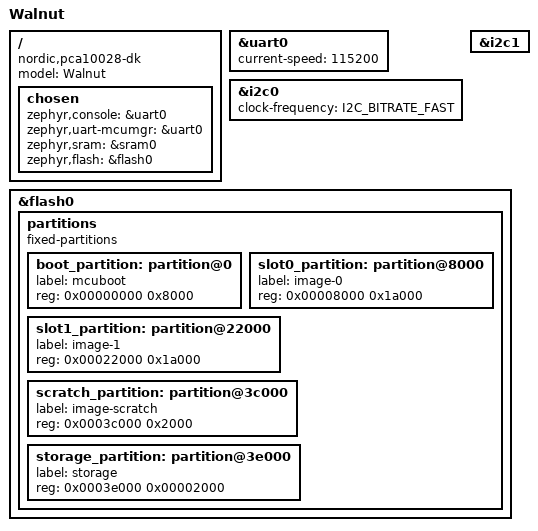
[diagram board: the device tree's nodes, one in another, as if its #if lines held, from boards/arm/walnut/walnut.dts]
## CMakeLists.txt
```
# Re-direct the directory where the 'boards' directory is found from
# $ZEPHYR_BASE to this directory.
set(BOARD_ROOT ${CMAKE_CURRENT_LIST_DIR})

set(BOARD walnut)

if(NOT BOARD_VARIANT)
    set(BOARD_VARIANT climate)
endif()

add_definitions(-DBOARD_VARIANT=${BOARD_VARIANT})

macro(set_conf_file)
    if(EXISTS ${APPLICATION_SOURCE_DIR}/boards/arm/walnut/${BOARD}_${BOARD_VARIANT}.conf)
        set(CONF_FILE "prj.conf ${APPLICATION_SOURCE_DIR}/boards/arm/walnut/${BOARD}_${BOARD_VARIANT}.conf")
    else()
        set(CONF_FILE "prj.conf")
    endif()
endmacro()

include($ENV{ZEPHYR_BASE}/cmake/app/boilerplate.cmake NO_POLICY_SCOPE)
project(NONE)

add_subdirectory(drivers)

FILE(GLOB app_sources src/*.c)
target_sources(app PRIVATE ${app_sources})
target_include_directories(app PRIVATE $ENV{ZEPHYR_BASE}/subsys/fs/nvs)
```

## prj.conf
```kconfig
#CONFIG_BT=y
CONFIG_BT_PERIPHERAL=y
CONFIG_BT_SMP=y
CONFIG_TINYCRYPT=y
CONFIG_BT_DEVICE_NAME="Walnut"
CONFIG_BT_DEVICE_APPEARANCE=0

#CONFIG_NEWLIB_LIBC=y
#CONFIG_NEWLIB_LIBC_FLOAT_PRINTF=y

#CONFIG_ASSERT=y
#CONFIG_ASSERT_LEVEL=2
#CONFIG_NUM_COOP_PRIORITIES=29
#CONFIG_NUM_PREEMPT_PRIORITIES=40

#CONFIG_SYS_POWER_MANAGEMENT=y
#CONFIG_SYS_POWER_LOW_POWER_STATE=y
#CONFIG_SYS_POWER_DEEP_SLEEP=y
#CONFIG_DEVICE_POWER_MANAGEMENT=y
#CONFIG_TICKLESS_IDLE=y
#CONFIG_TICKLESS_KERNEL=y
#CONFIG_GPIO=y

#CONFIG_MULTITHREADING=y

CONFIG_FLASH=y

CONFIG_NVS=y
CONFIG_NVS_LOG=y
CONFIG_NVS_LOG_LEVEL=4
CONFIG_REBOOT=y
```

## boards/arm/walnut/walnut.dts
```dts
/*
 * Copyright (c) 2017 Linaro Limited
 *
 * SPDX-License-Identifier: Apache-2.0
 */

/dts-v1/;
#include <nordic/nrf51822.dtsi>

/ {
	model = "Walnut";
	compatible = "nordic,pca10028-dk", "nordic,nrf51822-qfac",
		     "nordic,nrf51822";

	chosen {
		zephyr,console = &uart0;
#ifdef CONFIG_MCUMGR_SMP_UART
		zephyr,uart-mcumgr = &uart0;
#endif
		zephyr,sram = &sram0;
		zephyr,flash = &flash0;
	};
};

&uart0 {
	current-speed = <115200>;
	status = "ok";
};

&i2c0 {
	status = "ok";
	clock-frequency = <I2C_BITRATE_FAST>;
};

&i2c1 {
	status = "ok";
};

&flash0 {
	/*
	 * For more information, see:
	 * http://docs.zephyrproject.org/devices/dts/flash_partitions.html
	 */
	partitions {
		compatible = "fixed-partitions";
		#address-cells = <1>;
		#size-cells = <1>;

		boot_partition: partition@0 {
			label = "mcuboot";
			reg = <0x00000000 0x8000>;
		};
		slot0_partition: partition@8000 {
			label = "image-0";
			reg = <0x00008000 0x1a000>;
		};
		slot1_partition: partition@22000 {
			label = "image-1";
			reg = <0x00022000 0x1a000>;
		};
		scratch_partition: partition@3c000 {
			label = "image-scratch";
			reg = <0x0003c000 0x2000>;
		};

#if defined(CONFIG_FS_FLASH_STORAGE_PARTITION)
		storage_partition: partition@3e000 {
			label = "storage";
			reg = <0x0003e000 0x00002000>;
		};
#endif
	};
};
```

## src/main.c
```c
/* main.c - Application main entry point */

/*
 * Copyright (c) 2016 Intel Corporation
 *
 * SPDX-License-Identifier: Apache-2.0
 */

#include <stdint.h>
#include <zephyr.h>
#include <sensor.h>

#include "fg.h"
#include "nv.h"
#include "ble.h"
#include "ess.h"
#include "t_rh_sens.h"
#include "als.h"
#include "bp_sens.h"

#define CONFIG_SYS_LOG_MAIN_LEVEL 4

#define SYS_LOG_DOMAIN "app"
#define SYS_LOG_LEVEL CONFIG_SYS_LOG_MAIN_LEVEL
#include <logging/sys_log.h>


static void fg_update_cb(uint8_t battery_capacity)
{
    SYS_LOG_INF("Battery_capacity=%d", battery_capacity);
    ble_update_battery(battery_capacity);
}

static void t_rh_meas_cb(t_rh_meas_t *measurement)
{
    if (measurement->temperature_updated) {
        struct sensor_value *temperature = (struct sensor_value *)measurement->temperature;
        SYS_LOG_INF("T:%d.%06d", temperature->val1, temperature->val2);
        ble_update_temp(sensor_value_to_double(temperature));
    }

    if (measurement->humidity_updated) {
        struct sensor_value *humidity = (struct sensor_value *)measurement->humidity;
        SYS_LOG_INF("RH:%d.%06d", humidity->val1, humidity->val2);
        ble_update_humidity(sensor_value_to_double(humidity));
    }
}

static void al_meas_cb(struct sensor_value *ambient_light)
{
    SYS_LOG_INF("AL:%d.%06d", ambient_light->val1, ambient_light->val2);
    ble_update_ambient_light(sensor_value_to_double(ambient_light));
}

static void bp_meas_cb(struct sensor_value *baro_pressure)
{
    SYS_LOG_INF("AL:%d.%06d", baro_pressure->val1, baro_pressure->val2);
    ble_update_baro_pressure(sensor_value_to_double(baro_pressure));
}


void main(void)
{
    SYS_LOG_INF("Starting app");

    fg_init(fg_update_cb);
    nv_init();
    t_rh_sens_init(t_rh_meas_cb);
    als_init(al_meas_cb);
    bp_sens_init(bp_meas_cb);
    ble_init();

    while (1) {
        k_sleep(10 * MSEC_PER_SEC);
    }
}
```

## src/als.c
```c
/**
 *
 *
 *
 */

#include <stdlib.h>
#include <kernel.h>
#include <sensor.h>

#include "als.h"
#include "nv.h"
#include "ess.h"

#define CONFIG_SYS_LOG_ALS_LEVEL 1
#define SYS_LOG_DOMAIN "als"
#define SYS_LOG_LEVEL CONFIG_SYS_LOG_ALS_LEVEL
#include <logging/sys_log.h>


static struct device *tsl4531_dev;
static struct sensor_value als_val;
static struct k_timer meas_timer;
static struct k_work meas_work;
static als_meas_cb_t meas_cb;

static nv_sensor_data_t _default_sensor_data = {
    .sampling_func    = ESS_SAMPL_FUNC_INSTANTANEOUS,
    .meas_period      = ESS_MEAS_PERIOD_NOT_IN_USE,
    .update_interval  = 60,
    .application      = ESS_APPL_Air,
    .meas_uncertainty = 0,
};

static void meas_work_handler(struct k_work *work);
static void meas_timer_handler(struct k_timer *timer);


static void meas_work_handler(struct k_work *work)
{
    SYS_LOG_DBG("Periodic als measurement");
    als_meas();

    if (meas_cb != NULL) {
        meas_cb(&als_val);
    }
}

static void meas_timer_handler(struct k_timer *timer)
{
    k_work_submit(&meas_work);
}

int als_meas(void)
{
#ifdef CONFIG_TSL4531
    if (sensor_sample_fetch(tsl4531_dev)) {
        SYS_LOG_ERR("Error fetching tsl4531 sample");
        return -1;
    }

    if (sensor_channel_get(tsl4531_dev, SENSOR_CHAN_LIGHT, &als_val)) {
        SYS_LOG_ERR("Error reading tsl4531 data");
        return -1;
    } else {
        // SYS_LOG_DBG("AL:%d.%d", (int)sensor_value_to_double(&als_val),
        //             (int)(sensor_value_to_double(&als_val) * 100) % 100);
        // SYS_LOG_DBG("RH1:%d", rh_sensor_value.val1);
        // SYS_LOG_DBG("RH2:%d", rh_sensor_value.val2);
        SYS_LOG_INF("ALS:%d.%06d", als_val.val1, als_val.val2);
    }
#endif
    return 0;
}

void als_init(als_meas_cb_t callback)
{
#ifdef CONFIG_TSL4531
    int err;
    nv_sensor_data_t sensor_data;

    meas_cb = callback;

    tsl4531_dev = device_get_binding(CONFIG_TSL4531_NAME);
    if (tsl4531_dev == NULL) {
        SYS_LOG_ERR("Failed to get pointer to %s device!", CONFIG_TSL4531_NAME);
    }

    err = nv_get_sensor_data(NV_SENSOR_AMBIENT_LIGHT, &sensor_data);
    if (err == -ENOENT) {
        nv_set_sensor_data(NV_SENSOR_AMBIENT_LIGHT, &_default_sensor_data);
        nv_get_sensor_data(NV_SENSOR_AMBIENT_LIGHT, &sensor_data);
    }

    k_work_init(&meas_work, meas_work_handler);
    k_timer_init(&meas_timer, meas_timer_handler, NULL);
    k_timer_start(&meas_timer, K_SECONDS(5), K_SECONDS(sensor_data.update_interval));
#endif
}
```

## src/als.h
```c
/**
 *
 *
 */

#ifndef ALS_H
#define ALS_H

typedef void (*als_meas_cb_t)(struct sensor_value *ambient_light);

void als_init(als_meas_cb_t callback);
int als_meas(void);

#endif /* ALS_H */
```

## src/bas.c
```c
/** @file
 *  @brief BAS Service sample
 */

/*
 * Copyright (c) 2016 Intel Corporation
 *
 * SPDX-License-Identifier: Apache-2.0
 */

#include <zephyr/types.h>
#include <stddef.h>
#include <string.h>
#include <errno.h>
#include <misc/printk.h>
#include <misc/byteorder.h>
#include <zephyr.h>

#include <bluetooth/bluetooth.h>
#include <bluetooth/hci.h>
#include <bluetooth/conn.h>
#include <bluetooth/uuid.h>
#include <bluetooth/gatt.h>

static struct bt_gatt_ccc_cfg  blvl_ccc_cfg[BT_GATT_CCC_MAX] = {};
static u8_t is_notify_enabled;
static u8_t battery = 100;

static void blvl_ccc_cfg_changed(const struct bt_gatt_attr *attr,
                 u16_t value)
{
    is_notify_enabled = (value == BT_GATT_CCC_NOTIFY) ? 1 : 0;
}

static ssize_t read_blvl(struct bt_conn *conn, const struct bt_gatt_attr *attr,
             void *buf, u16_t len, u16_t offset)
{
    const char *value = attr->user_data;

    return bt_gatt_attr_read(conn, attr, buf, len, offset, value,
                 sizeof(*value));
}

/* Battery Service Declaration */
static struct bt_gatt_attr attrs[] = {
    BT_GATT_PRIMARY_SERVICE(BT_UUID_BAS),
    BT_GATT_CHARACTERISTIC(BT_UUID_BAS_BATTERY_LEVEL,
                   BT_GATT_CHRC_READ | BT_GATT_CHRC_NOTIFY,
                   BT_GATT_PERM_READ, read_blvl, NULL, &battery),
    BT_GATT_CCC(blvl_ccc_cfg, blvl_ccc_cfg_changed),
};

static struct bt_gatt_service bas_svc = BT_GATT_SERVICE(attrs);

void bas_init(void)
{
    bt_gatt_service_register(&bas_svc);
}

void bas_update(uint8_t capacity)
{
    battery = capacity;

    if (!is_notify_enabled) {
        return;
    }

    bt_gatt_notify(NULL, &attrs[2], &battery, sizeof(battery));
}
```

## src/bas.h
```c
/** @file
 *  @brief BAS Service sample
 */

/*
 * Copyright (c) 2016 Intel Corporation
 *
 * SPDX-License-Identifier: Apache-2.0
 */

#ifndef BAS_H
#define BAS_H

void bas_init(void);
void bas_update(uint8_t capacity);

#endif /* BAS_H */
```

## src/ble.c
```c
/**
 *
 *
 *
 */

#include <stdbool.h>
#include <zephyr/types.h>
#include <stddef.h>
#include <string.h>
#include <errno.h>
#include <misc/printk.h>
#include <misc/byteorder.h>
#include <zephyr.h>

#include <bluetooth/bluetooth.h>
#include <bluetooth/hci.h>
#include <bluetooth/conn.h>
#include <bluetooth/uuid.h>
#include <bluetooth/gatt.h>

#include "bas.h"
#include "dis.h"
#include "ess.h"

#define SYS_LOG_DOMAIN "BLE"
// #define SYS_LOG_LEVEL CONFIG_SYS_LOG_SENSOR_LEVEL
#include <logging/sys_log.h>

#define DEVICE_NAME				CONFIG_BT_DEVICE_NAME
#define DEVICE_NAME_LEN				(sizeof(DEVICE_NAME) - 1)

#ifndef BUILD_VERSION
#define BUILD_VERSION UNKNOWN
#endif

#define DEVICE_SOFTWARE_VERSION     STRINGIFY(BUILD_VERSION)
#define DEVICE_HARDWARE_VERSION     STRINGIFY(BOARD_VARIANT)

#define ESS_ADV_SLOW BT_LE_ADV_PARAM(BT_LE_ADV_OPT_CONNECTABLE, \
                       BT_GAP_ADV_SLOW_INT_MIN, \
                       BT_GAP_ADV_SLOW_INT_MAX)

#define ESS_ADV_FAST_1 BT_LE_ADV_PARAM(BT_LE_ADV_OPT_CONNECTABLE, \
                       BT_GAP_ADV_FAST_INT_MIN_1, \
                       BT_GAP_ADV_FAST_INT_MAX_1)

#define ESS_ADV_FAST_2 BT_LE_ADV_PARAM(BT_LE_ADV_OPT_CONNECTABLE, \
                       BT_GAP_ADV_FAST_INT_MIN_2, \
                       BT_GAP_ADV_FAST_INT_MAX_2)

// Default Device Information Service data
static dis_data_t dis_data = {
    .sw_rev = DEVICE_SOFTWARE_VERSION,
    .hw_rev = DEVICE_HARDWARE_VERSION,
};


static uint8_t batt[3] = { 0x0f, 0x18, 0x00 };

static struct bt_data ad[] = {
    BT_DATA_BYTES(BT_DATA_FLAGS, (BT_LE_AD_GENERAL | BT_LE_AD_NO_BREDR)),
    BT_DATA_BYTES(BT_DATA_UUID16_SOME, 0x1a, 0x18),
    BT_DATA(BT_DATA_NAME_COMPLETE, DEVICE_NAME, DEVICE_NAME_LEN),
    BT_DATA(BT_DATA_SVC_DATA16, batt, 3),
};

// static struct bt_data sd[] = {
//     BT_DATA(BT_DATA_NAME_COMPLETE, DEVICE_NAME, DEVICE_NAME_LEN),
// };

static void connected(struct bt_conn *conn, u8_t err)
{
    if (err) {
        SYS_LOG_ERR("Connection failed (err %u)", err);
    } else {
        SYS_LOG_DBG("Connected");


    // struct bt_le_conn_param param = {
    //     .interval_min = 24,
    //     // .interval_max = 40,
    //     .interval_max = 100,
    //     .latency = 0,
    //     .timeout = 400,
    // };
    // bt_conn_le_param_update(conn, &param);

    struct bt_conn_info info;
    bt_conn_get_info(conn, &info);

    struct bt_conn_le_info *le = &info.le;

    SYS_LOG_INF("Interval:%d", le->interval);
    SYS_LOG_INF("Latency:%d", le->latency);
    SYS_LOG_INF("Timeout:%d", le->timeout);

        // struct bt_le_conn_param param = {
        //     .interval_min = 24,
        //     .interval_max = 40,
        //     .latency = 0,
        //     .timeout = 400,
        // };
        // bt_conn_le_param_update(conn, &param);
    }
}

static void disconnected(struct bt_conn *conn, u8_t reason)
{
    SYS_LOG_DBG("Disconnected (reason %u)", reason);
}

static void le_param_updated(struct bt_conn *conn, u16_t interval,
                u16_t latency, u16_t timeout)
{
    SYS_LOG_INF("U:Interval:%d", interval);
    SYS_LOG_INF("U:Latency:%d", latency);
    SYS_LOG_INF("U:Timeout:%d", timeout);
}

static struct bt_conn_cb conn_callbacks = {
    .connected = connected,
    .disconnected = disconnected,
    .le_param_updated = le_param_updated,
};

static void bt_ready(int err)
{
    if (err) {
        SYS_LOG_ERR("Bluetooth init failed (err %d)", err);
        return;
    }

    SYS_LOG_INF("Bluetooth initialized");

    dis_init(&dis_data);
    ess_init();
    bas_init();

    err = bt_le_adv_start(ESS_ADV_SLOW, ad, ARRAY_SIZE(ad),
                //   sd, ARRAY_SIZE(sd));
                  NULL, 0);
    if (err) {
        SYS_LOG_ERR("Advertising failed to start (err %d)", err);
        return;
    }

    SYS_LOG_INF("Advertising successfully started");
}

static void auth_passkey_display(struct bt_conn *conn, unsigned int passkey)
{
    char addr[BT_ADDR_LE_STR_LEN];

    bt_addr_le_to_str(bt_conn_get_dst(conn), addr, sizeof(addr));

    printk("Passkey for %s: %06u", addr, passkey);
}

static void auth_cancel(struct bt_conn *conn)
{
    char addr[BT_ADDR_LE_STR_LEN];

    bt_addr_le_to_str(bt_conn_get_dst(conn), addr, sizeof(addr));

    printk("Pairing cancelled: %s", addr);
}

static struct bt_conn_auth_cb auth_cb_display = {
    .passkey_display = auth_passkey_display,
    .passkey_entry = NULL,
    .cancel = auth_cancel,
};

static void adv_update(uint8_t batt_capacity)
{
    int err;

    err = bt_le_adv_stop();
    if (err) {
        SYS_LOG_ERR("Failed to stop advertising");
    }

    batt[2] = batt_capacity;

    err = bt_le_adv_start(ESS_ADV_SLOW, ad, ARRAY_SIZE(ad), NULL, 0);
    if (err) {
        SYS_LOG_ERR("start error");
    }
}

void ble_update_temp(double temperature)
{
    ess_temperature_update((int16_t)(100 * temperature));
}

void ble_update_humidity(double humidity)
{
    ess_humidity_update((int16_t)(100 * humidity));
}

void ble_update_ambient_light(double ambient_light)
{
    ess_als_update((int16_t)(100 * ambient_light));
}

void ble_update_baro_pressure(double pressure)
{
    ess_baro_press_update((uint32_t)(10000 * pressure));
}

void ble_update_battery(uint8_t battery_capacity)
{
    adv_update(battery_capacity);
    bas_update(battery_capacity);
}

void ble_init(void)
{
    int err;

    SYS_LOG_INF("Initializing BLE");

    err = bt_enable(bt_ready);
    if (err) {
        SYS_LOG_ERR("Bluetooth init failed (err %d)", err);
        return;
    }

    bt_conn_cb_register(&conn_callbacks);
    bt_conn_auth_cb_register(&auth_cb_display);
}
```

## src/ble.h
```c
/**
 *
 *
 */
#ifndef BLE_H
#define BLE_H

void ble_init(void);

void ble_update_temp(double temperature);
void ble_update_humidity(double humidity);
void ble_update_ambient_light(double ambient_light);
void ble_update_baro_pressure(double pressure);
void ble_update_battery(uint8_t battery_capacity);

#endif /* BLE_H */
```

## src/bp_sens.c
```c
/**
 *
 *
 *
 */

#include <stdlib.h>
#include <kernel.h>
#include <sensor.h>

#include "bp_sens.h"
#include "nv.h"
#include "ess.h"

#define CONFIG_SYS_LOG_BP_SENS_LEVEL 1
#define SYS_LOG_DOMAIN "bp_sens"
#define SYS_LOG_LEVEL CONFIG_SYS_LOG_BP_SENS_LEVEL
#include <logging/sys_log.h>


static struct device *bmp280_dev;
static struct sensor_value bp_val;
static struct k_timer meas_timer;
static struct k_work meas_work;
static bp_meas_cb_t meas_cb;

static nv_sensor_data_t _default_sensor_data = {
    .sampling_func    = ESS_SAMPL_FUNC_INSTANTANEOUS,
    .meas_period      = ESS_MEAS_PERIOD_NOT_IN_USE,
    .update_interval  = 60,
    .application      = ESS_APPL_Air,
    .meas_uncertainty = 0,
};

static void meas_work_handler(struct k_work *work);
static void meas_timer_handler(struct k_timer *timer);


static void meas_work_handler(struct k_work *work)
{
    SYS_LOG_DBG("Periodic barometric pressure measurement");
    bp_sens_meas();

    if (meas_cb != NULL) {
        meas_cb(&bp_val);
    }

}

static void meas_timer_handler(struct k_timer *timer)
{
    k_work_submit(&meas_work);
}

void bp_sens_meas(void)
{
    int err;

    err = sensor_sample_fetch(bmp280_dev);
    if (err != 0) {
        SYS_LOG_ERR("Error fetching barometric pressure sample");
        return;
    }

    err = sensor_channel_get(bmp280_dev, SENSOR_CHAN_PRESS, &bp_val);
    if (err != 0) {
        SYS_LOG_ERR("Error reading bmp280 data");
    } else {
        SYS_LOG_INF("BP:%d.%06d", bp_val.val1, bp_val.val2);
    }
}

void bp_sens_init(bp_meas_cb_t callback)
{
#ifdef CONFIG_BMP280
    int err;
    nv_sensor_data_t sensor_data;

    meas_cb = callback;

    bmp280_dev = device_get_binding(CONFIG_BMP280_DEV_NAME);
    if (bmp280_dev == NULL) {
        SYS_LOG_ERR("Failed to get pointer to %s device!", CONFIG_BMP280_DEV_NAME);
    }

    err = nv_get_sensor_data(NV_SENSOR_BARO_PRESSURE, &sensor_data);
    if (err == -ENOENT) {
        nv_set_sensor_data(NV_SENSOR_BARO_PRESSURE, &_default_sensor_data);
        nv_get_sensor_data(NV_SENSOR_BARO_PRESSURE, &sensor_data);
    }

    k_work_init(&meas_work, meas_work_handler);
    k_timer_init(&meas_timer, meas_timer_handler, NULL);
    k_timer_start(&meas_timer, K_SECONDS(5), K_SECONDS(sensor_data.update_interval));
#endif
}
```

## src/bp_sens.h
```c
/**
 *
 *
 */

#ifndef BP_SENS_H
#define BP_SENS_H

typedef void (*bp_meas_cb_t)(struct sensor_value *baro_pressure);

void bp_sens_init(bp_meas_cb_t callback);
void bp_sens_meas(void);

#endif /* BP_SENS_H */
```

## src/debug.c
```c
    // u32_t *hej = (u32_t *)0x40003500;
    // SYS_LOG_INF("P:%p V:0x%08x V2:0x%08x", hej, *hej, *(u32_t *)0x40003500);
    // hej = (u32_t *)0x40003508;
    // SYS_LOG_INF("P:%p V:0x%08x V2:0x%08x", hej, *hej, *(u32_t *)0x40003508);
    // hej = (u32_t *)0x4000350C;
    // SYS_LOG_INF("P:%p V:0x%08x V2:0x%08x", hej, *hej, *(u32_t *)0x4000350C);

    // u32_t *gpio_out = (u32_t *)0x50000504;
    // u32_t *gpio_in = (u32_t *)0x50000510;
    // u32_t *gpio_dir = (u32_t *)0x50000514;
    // u32_t *gpio_pin_cnf_13 = (u32_t *)0x50000734;

    // SYS_LOG_INF("gpio_out P:%p V:0x%08x", gpio_out, *gpio_out);
    // SYS_LOG_INF("gpio_in P:%p V:0x%08x", gpio_in, *gpio_in);
    // SYS_LOG_INF("gpio_dir P:%p V:0x%08x", gpio_dir, *gpio_dir);
    // SYS_LOG_INF("gpio_pin_cnf_13 P:%p V:0x%08x", gpio_pin_cnf_13, *gpio_pin_cnf_13);
```

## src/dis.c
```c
/** @file
 *  @brief DIS Service sample
 */

/*
 * Copyright (c) 2016 Intel Corporation
 *
 * SPDX-License-Identifier: Apache-2.0
 */

#include <zephyr/types.h>
#include <stddef.h>
#include <string.h>
#include <errno.h>
#include <misc/printk.h>
#include <misc/byteorder.h>
#include <zephyr.h>

#include <bluetooth/bluetooth.h>
#include <bluetooth/hci.h>
#include <bluetooth/conn.h>
#include <bluetooth/uuid.h>
#include <bluetooth/gatt.h>

#include "dis.h"

// Device Information Service data
static dis_data_t *dis;

// Function prototype for reading software version
static ssize_t read_sw_vers(struct bt_conn *conn,
              const struct bt_gatt_attr *attr, void *buf,
              u16_t len, u16_t offset);

// Function prototype for reading hardware version
static ssize_t read_hw_vers(struct bt_conn *conn,
              const struct bt_gatt_attr *attr, void *buf,
              u16_t len, u16_t offset);

/* Device Information Service Declaration */
static struct bt_gatt_attr attrs[] = {
    BT_GATT_PRIMARY_SERVICE(BT_UUID_DIS),
    BT_GATT_CHARACTERISTIC(BT_UUID_DIS_SOFTWARE_REVISION,
                   BT_GATT_CHRC_READ, BT_GATT_PERM_READ,
                   read_sw_vers, NULL, NULL),
    BT_GATT_CHARACTERISTIC(BT_UUID_DIS_HARDWARE_REVISION,
                   BT_GATT_CHRC_READ, BT_GATT_PERM_READ,
                   read_hw_vers, NULL, NULL),
};
static struct bt_gatt_service dis_svc = BT_GATT_SERVICE(attrs);


/**
* @private
* @brief Callback to read the software version characteristic
*/
static ssize_t read_sw_vers(struct bt_conn *conn,
              const struct bt_gatt_attr *attr, void *buf,
              u16_t len, u16_t offset)
{
    return bt_gatt_attr_read(conn, attr, buf, len, offset, dis->sw_rev,
                 strlen(dis->sw_rev));
}

/**
* @private
* @brief Callback to read the hardware version characteristic
*/
static ssize_t read_hw_vers(struct bt_conn *conn,
              const struct bt_gatt_attr *attr, void *buf,
              u16_t len, u16_t offset)
{
    return bt_gatt_attr_read(conn, attr, buf, len, offset, dis->hw_rev,
                 strlen(dis->hw_rev));
}


/****************************************************************************
* Public Function Definitions
***************************************************************************/

void dis_init(dis_data_t *dis_data)
{
    dis = dis_data;

    bt_gatt_service_register(&dis_svc);
}
```

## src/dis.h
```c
/** @file
 *  @brief DIS Service sample
 */

/*
 * Copyright (c) 2016 Intel Corporation
 *
 * SPDX-License-Identifier: Apache-2.0
 */

#ifndef _DIS_H_
#define _DIS_H_

typedef struct {
    char *sw_rev;
    char *hw_rev;
} dis_data_t;

void dis_init(dis_data_t *dis_data);

#endif  /* _DIS_H_ */
```

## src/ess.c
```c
/** @file
 *  @brief Environmental Sensor Service
 */

/****************************************************************************
* Include Directives
***************************************************************************/

#include <zephyr/types.h>
#include <stddef.h>
#include <string.h>
#include <errno.h>
#include <misc/printk.h>
#include <misc/byteorder.h>
#include <zephyr.h>

#include <bluetooth/bluetooth.h>
#include <bluetooth/hci.h>
#include <bluetooth/conn.h>
#include <bluetooth/uuid.h>
#include <bluetooth/gatt.h>

#include "ess.h"
#include "nv.h"

#define SYS_LOG_DOMAIN "ESS"
#define SYS_LOG_LEVEL 1
#include <logging/sys_log.h>


/****************************************************************************
* Preprocessor Directives
***************************************************************************/

#define TEMPERATURE_SENSOR_NAME     "Temperature Sensor"
#define HUMIDITY_SENSOR_NAME        "Humidity Sensor"
#define AMBIENT_LIGHT_SENSOR_NAME   "Ambient Light Sensor"
#define BARO_PRESSURE_SENSOR_NAME   "Barometric Pressure Sensor"

/* ESS Trigger Setting conditions */
#define ESS_TRIGGER_INACTIVE                0x00
#define ESS_FIXED_TIME_INTERVAL             0x01
#define ESS_NO_LESS_THAN_SPECIFIED_TIME     0x02
#define ESS_VALUE_CHANGED                   0x03
#define ESS_LESS_THAN_REF_VALUE             0x04
#define ESS_LESS_OR_EQUAL_TO_REF_VALUE      0x05
#define ESS_GREATER_THAN_REF_VALUE          0x06
#define ESS_GREATER_OR_EQUAL_TO_REF_VALUE   0x07
#define ESS_EQUAL_TO_REF_VALUE              0x08
#define ESS_NOT_EQUAL_TO_REF_VALUE          0x09


/****************************************************************************
* Private Type Declarations
***************************************************************************/

struct ess_meas_desc {
    u16_t flags; /* Reserved for Future Use */
    u8_t sampling_func;
    u32_t meas_period;
    u32_t update_interval;
    u8_t application;
    u8_t meas_uncertainty;
};

struct ess_sensor {
    s16_t value;

    /* Valid Range */
    s16_t lower_limit;
    s16_t upper_limit;

    /* ES trigger setting - Value Notification condition */
    u8_t condition;
    union {
        u32_t seconds;
        s16_t ref_val;
    };

    struct bt_gatt_ccc_cfg  ccc_cfg[BT_GATT_CCC_MAX];
    struct ess_meas_desc meas_desc;
};

struct ess_pressure_sensor {
    u32_t value;

    /* Valid Range */
    u32_t lower_limit;
    u32_t upper_limit;

    /* ES trigger setting - Value Notification condition */
    u8_t condition;
    union {
        u32_t seconds;
        u32_t ref_val; /* Reference temperature */
    };

    struct bt_gatt_ccc_cfg  ccc_cfg[BT_GATT_CCC_MAX];
    struct ess_meas_desc meas_desc;
};

struct read_es_measurement_rp {
    u16_t flags; /* Reserved for Future Use */
    u8_t sampling_function;
    u8_t measurement_period[3];
    u8_t update_interval[3];
    u8_t application;
    u8_t measurement_uncertainty;
} __packed;

struct es_trigger_setting_seconds {
    u8_t condition;
    u8_t sec[3];
} __packed;

struct es_trigger_setting_reference {
    u8_t condition;
    s16_t ref_val;
} __packed;


/****************************************************************************
* Private Data Definitions
***************************************************************************/

static struct ess_sensor            _temperature;
static struct ess_sensor            _humidity;
static struct ess_sensor            _ambient_light;
static struct ess_pressure_sensor   _baro_pressure;

static u8_t _is_temp_notify_enabled;
static u8_t _is_humidity_notify_enabled;
static u8_t _is_ambient_light_notify_enabled;
static u8_t _is_baro_pressure_notify_enabled;

static ssize_t read_u16_value(struct bt_conn *conn, const struct bt_gatt_attr *attr,
            void *buf, u16_t len, u16_t offset);
static ssize_t read_u32_value(struct bt_conn *conn, const struct bt_gatt_attr *attr,
            void *buf, u16_t len, u16_t offset);
static ssize_t read_es_measurement(struct bt_conn *conn,
                   const struct bt_gatt_attr *attr, void *buf,
                   u16_t len, u16_t offset);
static ssize_t read_valid_range(struct bt_conn *conn,
                     const struct bt_gatt_attr *attr, void *buf,
                     u16_t len, u16_t offset);
static ssize_t read_valid_range_32(struct bt_conn *conn,
                     const struct bt_gatt_attr *attr, void *buf,
                     u16_t len, u16_t offset);
static void temp_ccc_cfg_changed(const struct bt_gatt_attr *attr,
                 u16_t value);
static void rh_ccc_cfg_changed(const struct bt_gatt_attr *attr,
                 u16_t value);
static void al_ccc_cfg_changed(const struct bt_gatt_attr *attr,
                 u16_t value);
static void bp_ccc_cfg_changed(const struct bt_gatt_attr *attr,
                 u16_t value);
static ssize_t read_trigger_setting(struct bt_conn *conn,
                     const struct bt_gatt_attr *attr,
                     void *buf, u16_t len,
                     u16_t offset);
static ssize_t read_trigger_setting_32(struct bt_conn *conn,
                     const struct bt_gatt_attr *attr,
                     void *buf, u16_t len,
                     u16_t offset);


static struct bt_gatt_attr ess_attrs[] = {
    BT_GATT_PRIMARY_SERVICE(BT_UUID_ESS),

    /* Temperature Sensor */
    BT_GATT_CHARACTERISTIC(BT_UUID_TEMPERATURE,
                    BT_GATT_CHRC_READ | BT_GATT_CHRC_NOTIFY,
                    BT_GATT_PERM_READ,
                    read_u16_value, NULL, &_temperature.value),
    BT_GATT_CUD(TEMPERATURE_SENSOR_NAME, BT_GATT_PERM_READ),
    BT_GATT_DESCRIPTOR(BT_UUID_ES_MEASUREMENT, BT_GATT_PERM_READ,
                    read_es_measurement, NULL, &_temperature.meas_desc),
    BT_GATT_DESCRIPTOR(BT_UUID_VALID_RANGE,
                    BT_GATT_PERM_READ,
                    read_valid_range, NULL, &_temperature),
    BT_GATT_DESCRIPTOR(BT_UUID_ES_TRIGGER_SETTING,
               BT_GATT_PERM_READ, read_trigger_setting,
               NULL, &_temperature),
    BT_GATT_CCC(_temperature.ccc_cfg, temp_ccc_cfg_changed),

    /* Humidity Sensor */
    BT_GATT_CHARACTERISTIC(BT_UUID_HUMIDITY,
                    BT_GATT_CHRC_READ | BT_GATT_CHRC_NOTIFY,
                    BT_GATT_PERM_READ,
                    read_u16_value, NULL, &_humidity.value),
    BT_GATT_CUD(HUMIDITY_SENSOR_NAME, BT_GATT_PERM_READ),
    BT_GATT_DESCRIPTOR(BT_UUID_ES_MEASUREMENT, BT_GATT_PERM_READ,
               read_es_measurement, NULL, &_humidity.meas_desc),
    BT_GATT_DESCRIPTOR(BT_UUID_VALID_RANGE,
                    BT_GATT_PERM_READ,
                    read_valid_range, NULL, &_humidity),
    BT_GATT_DESCRIPTOR(BT_UUID_ES_TRIGGER_SETTING,
               BT_GATT_PERM_READ, read_trigger_setting,
               NULL, &_humidity),
    BT_GATT_CCC(_humidity.ccc_cfg, rh_ccc_cfg_changed),

    /* Ambient Light Sensor */
    BT_GATT_CHARACTERISTIC(BT_UUID_IRRADIANCE,
                    BT_GATT_CHRC_READ | BT_GATT_CHRC_NOTIFY,
                    BT_GATT_PERM_READ,
                    read_u16_value, NULL, &_ambient_light.value),
    BT_GATT_CUD(AMBIENT_LIGHT_SENSOR_NAME, BT_GATT_PERM_READ),
    BT_GATT_DESCRIPTOR(BT_UUID_ES_MEASUREMENT, BT_GATT_PERM_READ,
               read_es_measurement, NULL, &_ambient_light.meas_desc),
    BT_GATT_DESCRIPTOR(BT_UUID_VALID_RANGE,
                    BT_GATT_PERM_READ,
                    read_valid_range, NULL, &_ambient_light),
    BT_GATT_DESCRIPTOR(BT_UUID_ES_TRIGGER_SETTING,
               BT_GATT_PERM_READ, read_trigger_setting,
               NULL, &_ambient_light),
    BT_GATT_CCC(_ambient_light.ccc_cfg, al_ccc_cfg_changed),

    /* Barometric Pressure Sensor */
    BT_GATT_CHARACTERISTIC(BT_UUID_PRESSURE,
                    BT_GATT_CHRC_READ | BT_GATT_CHRC_NOTIFY,
                    BT_GATT_PERM_READ,
                    read_u32_value, NULL, &_baro_pressure.value),
    BT_GATT_CUD(BARO_PRESSURE_SENSOR_NAME, BT_GATT_PERM_READ),
    BT_GATT_DESCRIPTOR(BT_UUID_ES_MEASUREMENT, BT_GATT_PERM_READ,
               read_es_measurement, NULL, &_baro_pressure.meas_desc),
    BT_GATT_DESCRIPTOR(BT_UUID_VALID_RANGE,
                    BT_GATT_PERM_READ,
                    read_valid_range_32, NULL, &_baro_pressure),
    BT_GATT_DESCRIPTOR(BT_UUID_ES_TRIGGER_SETTING,
               BT_GATT_PERM_READ, read_trigger_setting_32,
               NULL, &_baro_pressure),
    BT_GATT_CCC(_baro_pressure.ccc_cfg, bp_ccc_cfg_changed),
};

static struct bt_gatt_service ess_svc = BT_GATT_SERVICE(ess_attrs);


/****************************************************************************
* Public Data Definitions
***************************************************************************/


/****************************************************************************
* Private Function Definitions
***************************************************************************/

static inline void int_to_le24(u32_t value, u8_t *u24)
{
    u24[0] = value & 0xff;
    u24[1] = (value >> 8) & 0xff;
    u24[2] = (value >> 16) & 0xff;
}

static inline u32_t le24_to_int(const u8_t *u24)
{
    return ((u32_t)u24[0] |
        (u32_t)u24[1] << 8 |
        (u32_t)u24[2] << 16);
}


static ssize_t read_u16_value(struct bt_conn *conn, const struct bt_gatt_attr *attr,
            void *buf, u16_t len, u16_t offset)
{
    const u16_t *u16 = attr->user_data;
    u16_t value = sys_cpu_to_le16(*u16);

    return bt_gatt_attr_read(conn, attr, buf, len, offset, &value,
                 sizeof(value));
}

static ssize_t read_u32_value(struct bt_conn *conn, const struct bt_gatt_attr *attr,
            void *buf, u16_t len, u16_t offset)
{
    const u32_t *u32 = attr->user_data;
    u32_t value = sys_cpu_to_le32(*u32);

    return bt_gatt_attr_read(conn, attr, buf, len, offset, &value,
                 sizeof(value));
}


static void temp_ccc_cfg_changed(const struct bt_gatt_attr *attr,
                 u16_t value)
{
    _is_temp_notify_enabled = (value == BT_GATT_CCC_NOTIFY) ? 1 : 0;
}

static void rh_ccc_cfg_changed(const struct bt_gatt_attr *attr,
                 u16_t value)
{
    _is_humidity_notify_enabled = (value == BT_GATT_CCC_NOTIFY) ? 1 : 0;
}

static void al_ccc_cfg_changed(const struct bt_gatt_attr *attr,
                 u16_t value)
{
    _is_ambient_light_notify_enabled = (value == BT_GATT_CCC_NOTIFY) ? 1 : 0;
}

static void bp_ccc_cfg_changed(const struct bt_gatt_attr *attr,
                 u16_t value)
{
    _is_baro_pressure_notify_enabled = (value == BT_GATT_CCC_NOTIFY) ? 1 : 0;
}


static ssize_t read_es_measurement(struct bt_conn *conn,
                   const struct bt_gatt_attr *attr, void *buf,
                   u16_t len, u16_t offset)
{
    const struct ess_meas_desc *value = attr->user_data;
    struct read_es_measurement_rp rsp;

    rsp.flags = sys_cpu_to_le16(value->flags);
    rsp.sampling_function = value->sampling_func;
    int_to_le24(value->meas_period, rsp.measurement_period);
    int_to_le24(value->update_interval, rsp.update_interval);
    rsp.application = value->application;
    rsp.measurement_uncertainty = value->meas_uncertainty;

    return bt_gatt_attr_read(conn, attr, buf, len, offset, &rsp,
                 sizeof(rsp));
}

static ssize_t read_valid_range(struct bt_conn *conn,
                     const struct bt_gatt_attr *attr, void *buf,
                     u16_t len, u16_t offset)
{
    const struct ess_sensor *sensor = attr->user_data;
    u16_t tmp[] = {sys_cpu_to_le16(sensor->lower_limit),
              sys_cpu_to_le16(sensor->upper_limit)};

    return bt_gatt_attr_read(conn, attr, buf, len, offset, tmp,
                 sizeof(tmp));
}

static ssize_t read_valid_range_32(struct bt_conn *conn,
                     const struct bt_gatt_attr *attr, void *buf,
                     u16_t len, u16_t offset)
{
    const struct ess_pressure_sensor *sensor = attr->user_data;
    u32_t tmp[] = {sys_cpu_to_le32(sensor->lower_limit),
              sys_cpu_to_le32(sensor->upper_limit)};

    return bt_gatt_attr_read(conn, attr, buf, len, offset, tmp,
                 sizeof(tmp));
}

static ssize_t read_trigger_setting(struct bt_conn *conn,
                     const struct bt_gatt_attr *attr,
                     void *buf, u16_t len,
                     u16_t offset)
{
    const struct ess_sensor *sensor = attr->user_data;

    switch (sensor->condition) {
    /* Operand N/A */
    case ESS_TRIGGER_INACTIVE:
        /* fallthrough */
    case ESS_VALUE_CHANGED:
        return bt_gatt_attr_read(conn, attr, buf, len, offset,
                     &sensor->condition,
                     sizeof(sensor->condition));
    /* Seconds */
    case ESS_FIXED_TIME_INTERVAL:
        /* fallthrough */
    case ESS_NO_LESS_THAN_SPECIFIED_TIME: {
            struct es_trigger_setting_seconds rp;

            rp.condition = sensor->condition;
            int_to_le24(sensor->seconds, rp.sec);

            return bt_gatt_attr_read(conn, attr, buf, len, offset,
                         &rp, sizeof(rp));
        }
    /* Reference value */
    default: {
            struct es_trigger_setting_reference rp;

            rp.condition = sensor->condition;
            rp.ref_val = sys_cpu_to_le16(sensor->ref_val);

            return bt_gatt_attr_read(conn, attr, buf, len, offset,
                         &rp, sizeof(rp));
        }
    }
}

static ssize_t read_trigger_setting_32(struct bt_conn *conn,
                     const struct bt_gatt_attr *attr,
                     void *buf, u16_t len,
                     u16_t offset)
{
    const struct ess_pressure_sensor *sensor = attr->user_data;

    switch (sensor->condition) {
    /* Operand N/A */
    case ESS_TRIGGER_INACTIVE:
        /* fallthrough */
    case ESS_VALUE_CHANGED:
        return bt_gatt_attr_read(conn, attr, buf, len, offset,
                     &sensor->condition,
                     sizeof(sensor->condition));
    /* Seconds */
    case ESS_FIXED_TIME_INTERVAL:
        /* fallthrough */
    case ESS_NO_LESS_THAN_SPECIFIED_TIME: {
            struct es_trigger_setting_seconds rp;

            rp.condition = sensor->condition;
            int_to_le24(sensor->seconds, rp.sec);

            return bt_gatt_attr_read(conn, attr, buf, len, offset,
                         &rp, sizeof(rp));
        }
    /* Reference value */
    default: {
            struct es_trigger_setting_reference rp;

            rp.condition = sensor->condition;
            rp.ref_val = sys_cpu_to_le16(sensor->ref_val);

            return bt_gatt_attr_read(conn, attr, buf, len, offset,
                         &rp, sizeof(rp));
        }
    }
}

static bool check_condition(u8_t condition, s16_t old_val, s16_t new_val,
                s16_t ref_val)
{
    switch (condition) {
    case ESS_TRIGGER_INACTIVE:
        return false;
    case ESS_FIXED_TIME_INTERVAL:
    case ESS_NO_LESS_THAN_SPECIFIED_TIME:
        /* TODO: Check time requirements */
        return false;
    case ESS_VALUE_CHANGED:
        return new_val != old_val;
    case ESS_LESS_THAN_REF_VALUE:
        return new_val < ref_val;
    case ESS_LESS_OR_EQUAL_TO_REF_VALUE:
        return new_val <= ref_val;
    case ESS_GREATER_THAN_REF_VALUE:
        return new_val > ref_val;
    case ESS_GREATER_OR_EQUAL_TO_REF_VALUE:
        return new_val >= ref_val;
    case ESS_EQUAL_TO_REF_VALUE:
        return new_val == ref_val;
    case ESS_NOT_EQUAL_TO_REF_VALUE:
        return new_val != ref_val;
    default:
        return false;
    }
}


static void ess_temperature_sensor_init()
{
    int err;
    nv_sensor_data_t sensor_data;
    struct ess_meas_desc *meas_desc = &_temperature.meas_desc;

    err = nv_get_sensor_data(NV_SENSOR_TEMPERATURE, &sensor_data);
    if (err) {
        SYS_LOG_ERR("Failed to get temperature NV data");
        return;
    }

    meas_desc->sampling_func    = sensor_data.sampling_func;
    meas_desc->meas_period      = sensor_data.meas_period;
    meas_desc->update_interval  = sensor_data.update_interval;
    meas_desc->application      = sensor_data.application;
    meas_desc->meas_uncertainty = sensor_data.meas_uncertainty;

    _temperature.condition = ESS_VALUE_CHANGED;
    _temperature.lower_limit = -4000;
    _temperature.upper_limit = 8500;
}

static void ess_humidity_sensor_init()
{
    int err;
    nv_sensor_data_t sensor_data;
    struct ess_meas_desc *meas_desc = &_humidity.meas_desc;

    err = nv_get_sensor_data(NV_SENSOR_HUMIDITY, &sensor_data);
    if (err) {
        SYS_LOG_ERR("Failed to get humidity NV data");
        return;
    }

    meas_desc->sampling_func    = sensor_data.sampling_func;
    meas_desc->meas_period      = sensor_data.meas_period;
    meas_desc->update_interval  = sensor_data.update_interval;
    meas_desc->application      = sensor_data.application;
    meas_desc->meas_uncertainty = sensor_data.meas_uncertainty;

    _humidity.condition = ESS_VALUE_CHANGED;
    _humidity.lower_limit = 0;
    _humidity.upper_limit = 10000;
}

static void ess_ambient_light_sensor_init()
{
    int err;
    nv_sensor_data_t sensor_data;
    struct ess_meas_desc *meas_desc = &_ambient_light.meas_desc;

    err = nv_get_sensor_data(NV_SENSOR_AMBIENT_LIGHT, &sensor_data);
    if (err) {
        SYS_LOG_ERR("Failed to get ambient light NV data");
        return;
    }

    meas_desc->sampling_func    = sensor_data.sampling_func;
    meas_desc->meas_period      = sensor_data.meas_period;
    meas_desc->update_interval  = sensor_data.update_interval;
    meas_desc->application      = sensor_data.application;
    meas_desc->meas_uncertainty = sensor_data.meas_uncertainty;

    _ambient_light.condition = ESS_VALUE_CHANGED;
    _ambient_light.lower_limit = 0;
    // _ambient_light.upper_limit = 655350;
    _ambient_light.upper_limit = 65535;
}

static void ess_baro_pressure_sensor_init()
{
    int err;
    nv_sensor_data_t sensor_data;
    struct ess_meas_desc *meas_desc = &_baro_pressure.meas_desc;

    err = nv_get_sensor_data(NV_SENSOR_BARO_PRESSURE, &sensor_data);
    if (err) {
        SYS_LOG_ERR("Failed to get barometric pressure NV data");
        return;
    }

    meas_desc->sampling_func    = sensor_data.sampling_func;
    meas_desc->meas_period      = sensor_data.meas_period;
    meas_desc->update_interval  = sensor_data.update_interval;
    meas_desc->application      = sensor_data.application;
    meas_desc->meas_uncertainty = sensor_data.meas_uncertainty;

    _baro_pressure.condition = ESS_VALUE_CHANGED;
    _baro_pressure.lower_limit = 950000;
    _baro_pressure.upper_limit = 1050000;
}


/****************************************************************************
* Public Function Definitions
***************************************************************************/

void ess_init(void)
{
    bt_gatt_service_register(&ess_svc);

    ess_temperature_sensor_init();
    ess_humidity_sensor_init();
    ess_ambient_light_sensor_init();
    ess_baro_pressure_sensor_init();
}

void ess_temperature_update(s16_t new_value)
{
    bool notify = check_condition(_temperature.condition,
                    _temperature.value, new_value,
                    _temperature.ref_val);

    /* Update temperature value */
    _temperature.value = new_value;

    if (!_is_temp_notify_enabled) {
        return;
    }

    /* Trigger notification if conditions are met */
    if (notify) {
        bt_gatt_notify(NULL, &ess_attrs[2], &_temperature.value, sizeof(_temperature.value));
    }

}

void ess_humidity_update(s16_t new_value)
{
    bool notify = check_condition(_humidity.condition,
                      _humidity.value, new_value,
                      _humidity.ref_val);

    /* Update humidity value */
    _humidity.value = new_value;

    if (!_is_humidity_notify_enabled) {
        return;
    }

    /* Trigger notification if conditions are met */
    if (notify) {
        bt_gatt_notify(NULL, &ess_attrs[9], &_humidity.value, sizeof(_humidity.value));
    }

}

void ess_als_update(s16_t new_value)
{
    bool notify = check_condition(_ambient_light.condition,
                      _ambient_light.value, new_value,
                      _ambient_light.ref_val);

    /* Update ambient light value */
    _ambient_light.value = new_value;

    if (!_is_ambient_light_notify_enabled) {
        return;
    }

    /* Trigger notification if conditions are met */
    if (notify) {
        bt_gatt_notify(NULL, &ess_attrs[16], &_ambient_light.value, sizeof(_ambient_light.value));
    }

}

void ess_baro_press_update(u32_t new_value)
{
    bool notify = check_condition(_baro_pressure.condition,
                      _baro_pressure.value, new_value,
                      _baro_pressure.ref_val);

    /* Update barometric pressure value */
    _baro_pressure.value = new_value;

    if (!_is_baro_pressure_notify_enabled) {
        return;
    }

    /* Trigger notification if conditions are met */
    if (notify) {
        bt_gatt_notify(NULL, &ess_attrs[23], &_baro_pressure.value, sizeof(_baro_pressure.value));
    }

}
```
